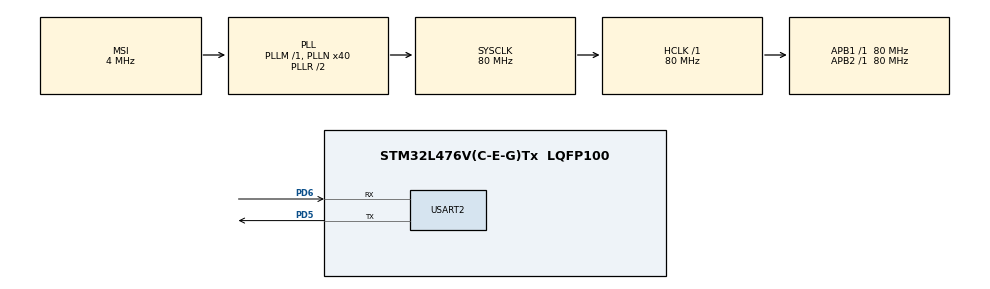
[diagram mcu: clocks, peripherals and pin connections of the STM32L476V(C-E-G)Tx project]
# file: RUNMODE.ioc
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Mcu.Family=STM32L4
Mcu.Name=STM32L476V(C-E-G)Tx
Mcu.Package=LQFP100
NVIC.PriorityGroup=NVIC_PRIORITYGROUP_4
PA13.Mode=Serial-Wire
PA13.Signal=SYS_JTMS-SWDIO
PA14.Mode=Serial-Wire
PA14.Signal=SYS_JTCK-SWCLK
PD5.Mode=Asynchronous
PD5.Signal=USART2_TX
PD6.Mode=Asynchronous
PD6.Signal=USART2_RX
ProjectManager.TargetToolchain=EWARM
RCC.ADCFreq_Value=16000000
RCC.AHBFreq_Value=80000000
RCC.APB1Freq_Value=80000000
RCC.APB1TimFreq_Value=80000000
RCC.APB2Freq_Value=80000000
RCC.APB2TimFreq_Value=80000000
RCC.CortexFreq_Value=80000000
RCC.HCLKFreq_Value=80000000
RCC.HSE_VALUE=8000000
RCC.HSI_VALUE=16000000
RCC.LSE_VALUE=32768
RCC.MSI_VALUE=4000000
RCC.PLLN=40
RCC.SYSCLKFreq_VALUE=80000000
RCC.SYSCLKSource=RCC_SYSCLKSOURCE_PLLCLK
RCC.USBFreq_Value=16000000
RCC.VCOOutputFreq_Value=160000000
TIM2.Period=0xFFFFFFFF
USART2.WordLength=UART_WORDLENGTH_8B
VP_TIM2_VS_ClockSourceINT.Mode=Internal
board=RUNMODE

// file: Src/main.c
/**
  ******************************************************************************
  * File Name          : main.c
  * Description        : Main program body
  ******************************************************************************
  *
  * COPYRIGHT(c) 2015 STMicroelectronics
  *
  * Redistribution and use in source and binary forms, with or without modification,
  * are permitted provided that the following conditions are met:
  *   1. Redistributions of source code must retain the above copyright notice,
  *      this list of conditions and the following disclaimer.
  *   2. Redistributions in binary form must reproduce the above copyright notice,
  *      this list of conditions and the following disclaimer in the documentation
  *      and/or other materials provided with the distribution.
  *   3. Neither the name of STMicroelectronics nor the names of its contributors
  *      may be used to endorse or promote products derived from this software
  *      without specific prior written permission.
  *
  * THIS SOFTWARE IS PROVIDED BY THE COPYRIGHT HOLDERS AND CONTRIBUTORS "AS IS"
  * AND ANY EXPRESS OR IMPLIED WARRANTIES, INCLUDING, BUT NOT LIMITED TO, THE
  * IMPLIED WARRANTIES OF MERCHANTABILITY AND FITNESS FOR A PARTICULAR PURPOSE ARE
  * DISCLAIMED. IN NO EVENT SHALL THE COPYRIGHT HOLDER OR CONTRIBUTORS BE LIABLE
  * FOR ANY DIRECT, INDIRECT, INCIDENTAL, SPECIAL, EXEMPLARY, OR CONSEQUENTIAL
  * DAMAGES (INCLUDING, BUT NOT LIMITED TO, PROCUREMENT OF SUBSTITUTE GOODS OR
  * SERVICES; LOSS OF USE, DATA, OR PROFITS; OR BUSINESS INTERRUPTION) HOWEVER
  * CAUSED AND ON ANY THEORY OF LIABILITY, WHETHER IN CONTRACT, STRICT LIABILITY,
  * OR TORT (INCLUDING NEGLIGENCE OR OTHERWISE) ARISING IN ANY WAY OUT OF THE USE
  * OF THIS SOFTWARE, EVEN IF ADVISED OF THE POSSIBILITY OF SUCH DAMAGE.
  *
  ******************************************************************************
  */
#include "stm32l4xx_hal.h"

/* USER CODE BEGIN Includes */
#include <stdio.h>
#include "coremark.h"
/* USER CODE END Includes */

TIM_HandleTypeDef htim2;

UART_HandleTypeDef huart2;

/* USER CODE BEGIN PV */
/* Private variables ---------------------------------------------------------*/
//struct __FILE { int dummy;};
//FILE __stdout;

/* USER CODE END PV */

void SystemClock_Config(void);
static void MX_GPIO_Init(void);
static void MX_TIM2_Init(void);
static void MX_USART2_UART_Init(void);

/* USER CODE BEGIN PFP */
/* Private function prototypes -----------------------------------------------*/
static void ART_Disable(void);
static void SystemClock_Config_MSI_24MHZ(void);
static void Clock_MSI24MHZ_Enable(void);

/* USER CODE END PFP */

int main(void)
{

  /* MCU Configuration----------------------------------------------------------*/

  /* Reset of all peripherals, Initializes the Flash interface and the Systick. */
  HAL_Init();

  /* Configure the system clock */
  SystemClock_Config();

  /* Initialize all configured peripherals */
  MX_GPIO_Init();
  MX_TIM2_Init();
  MX_USART2_UART_Init();

  /* USER CODE BEGIN 2 */

  //TPI->ACPR = (HAL_RCC_GetSysClockFreq() / 2000000) - 1; // make the SWO working whatever settings in the system frequency - output is always 2MHz

  //ART_Disable();
  //Clock_MSI24MHZ_Enable();

  HAL_TIM_Base_Start(&htim2);

  printf("\n");
  printf("Running from address:   0x%08X \n", (uint32_t)main_coremark);
  printf("Data at address: 0x%08X \n", (uint32_t)&default_num_contexts);
  //printf("WS: %2d, I_cache: %s, D_cache: %s, Prefetch: %s\n", FLASH->ACR & 0x0007, (FLASH->ACR & 0x0200)? "ON ":"OFF", ((FLASH->ACR & 0x0400)? "ON ":"OFF"), ((FLASH->ACR & 0x0100)? "ON ":"OFF"));
  printf("WS: %2d, ART: %s\n", FLASH->ACR & 0x0007, (FLASH->ACR & 0x0200)? "ON ":"OFF");
  printf("System Clock: %9d\n", HAL_RCC_GetSysClockFreq() );

  main_coremark();

  /* USER CODE END 2 */

  /* Infinite loop */
  while (1)
  {

  }

}

/** System Clock Configuration
*/
void SystemClock_Config(void)
{

  RCC_OscInitTypeDef RCC_OscInitStruct;
  RCC_ClkInitTypeDef RCC_ClkInitStruct;
  RCC_PeriphCLKInitTypeDef PeriphClkInit;

  RCC_OscInitStruct.OscillatorType = RCC_OSCILLATORTYPE_MSI;
  RCC_OscInitStruct.MSIState = RCC_MSI_ON;
  RCC_OscInitStruct.MSICalibrationValue = 0;
  RCC_OscInitStruct.MSIClockRange = RCC_MSIRANGE_6;
  RCC_OscInitStruct.PLL.PLLState = RCC_PLL_ON;
  RCC_OscInitStruct.PLL.PLLSource = RCC_PLLSOURCE_MSI;
  RCC_OscInitStruct.PLL.PLLM = 1;
  RCC_OscInitStruct.PLL.PLLN = 40;
  RCC_OscInitStruct.PLL.PLLP = RCC_PLLP_DIV7;
  RCC_OscInitStruct.PLL.PLLQ = RCC_PLLQ_DIV2;
  RCC_OscInitStruct.PLL.PLLR = RCC_PLLR_DIV2;
  HAL_RCC_OscConfig(&RCC_OscInitStruct);

  RCC_ClkInitStruct.ClockType = RCC_CLOCKTYPE_HCLK|RCC_CLOCKTYPE_SYSCLK
                              |RCC_CLOCKTYPE_PCLK1|RCC_CLOCKTYPE_PCLK2;
  RCC_ClkInitStruct.SYSCLKSource = RCC_SYSCLKSOURCE_PLLCLK;
  RCC_ClkInitStruct.AHBCLKDivider = RCC_SYSCLK_DIV1;
  RCC_ClkInitStruct.APB1CLKDivider = RCC_HCLK_DIV1;
  RCC_ClkInitStruct.APB2CLKDivider = RCC_HCLK_DIV1;
  HAL_RCC_ClockConfig(&RCC_ClkInitStruct, FLASH_LATENCY_4);

  PeriphClkInit.PeriphClockSelection = RCC_PERIPHCLK_USART2;
  PeriphClkInit.Usart2ClockSelection = RCC_USART2CLKSOURCE_PCLK1;
  HAL_RCCEx_PeriphCLKConfig(&PeriphClkInit);

  __PWR_CLK_ENABLE();

  HAL_PWREx_ControlVoltageScaling(PWR_REGULATOR_VOLTAGE_SCALE1);

  HAL_SYSTICK_Config(HAL_RCC_GetHCLKFreq()/1000);

  HAL_SYSTICK_CLKSourceConfig(SYSTICK_CLKSOURCE_HCLK);

  /* SysTick_IRQn interrupt configuration */
  HAL_NVIC_SetPriority(SysTick_IRQn, 0, 0);
}

/* TIM2 init function */
void MX_TIM2_Init(void)
{

  TIM_ClockConfigTypeDef sClockSourceConfig;
  TIM_MasterConfigTypeDef sMasterConfig;

  htim2.Instance = TIM2;
  htim2.Init.Prescaler = 0;
  htim2.Init.CounterMode = TIM_COUNTERMODE_UP;
  htim2.Init.Period = 0xFFFFFFFF;
  htim2.Init.ClockDivision = TIM_CLOCKDIVISION_DIV1;
  HAL_TIM_Base_Init(&htim2);

  sClockSourceConfig.ClockSource = TIM_CLOCKSOURCE_INTERNAL;
  HAL_TIM_ConfigClockSource(&htim2, &sClockSourceConfig);

  sMasterConfig.MasterOutputTrigger = TIM_TRGO_RESET;
  sMasterConfig.MasterSlaveMode = TIM_MASTERSLAVEMODE_DISABLE;
  HAL_TIMEx_MasterConfigSynchronization(&htim2, &sMasterConfig);

}

/* USART2 init function */
void MX_USART2_UART_Init(void)
{

  huart2.Instance = USART2;
  huart2.Init.BaudRate = 115200;
  huart2.Init.WordLength = UART_WORDLENGTH_8B;
  huart2.Init.StopBits = UART_STOPBITS_1;
  huart2.Init.Parity = UART_PARITY_NONE;
  huart2.Init.Mode = UART_MODE_TX_RX;
  huart2.Init.HwFlowCtl = UART_HWCONTROL_NONE;
  huart2.Init.OverSampling = UART_OVERSAMPLING_16;
  huart2.Init.OneBitSampling = UART_ONEBIT_SAMPLING_DISABLED;
  huart2.AdvancedInit.AdvFeatureInit = UART_ADVFEATURE_NO_INIT;
  HAL_UART_Init(&huart2);

}

/** Configure pins as
        * Analog
        * Input
        * Output
        * EVENT_OUT
        * EXTI
        * Free pins are configured automatically as Analog (this feature is enabled through
        * the Code Generation settings)
*/
void MX_GPIO_Init(void)
{

  GPIO_InitTypeDef GPIO_InitStruct;

  /* GPIO Ports Clock Enable */
  __GPIOE_CLK_ENABLE();
  __GPIOC_CLK_ENABLE();
  __GPIOH_CLK_ENABLE();
  __GPIOA_CLK_ENABLE();
  __GPIOB_CLK_ENABLE();
  __GPIOD_CLK_ENABLE();

  /*Configure GPIO pins : PE2 PE3 PE4 PE5
                           PE6 PE7 PE8 PE9
                           PE10 PE11 PE12 PE13
                           PE14 PE15 PE0 PE1 */
  GPIO_InitStruct.Pin = GPIO_PIN_2|GPIO_PIN_3|GPIO_PIN_4|GPIO_PIN_5
                          |GPIO_PIN_6|GPIO_PIN_7|GPIO_PIN_8|GPIO_PIN_9
                          |GPIO_PIN_10|GPIO_PIN_11|GPIO_PIN_12|GPIO_PIN_13
                          |GPIO_PIN_14|GPIO_PIN_15|GPIO_PIN_0|GPIO_PIN_1;
  GPIO_InitStruct.Mode = GPIO_MODE_ANALOG;
  GPIO_InitStruct.Pull = GPIO_NOPULL;
  HAL_GPIO_Init(GPIOE, &GPIO_InitStruct);

  /*Configure GPIO pins : PC13 PC14 PC15 PC0
                           PC1 PC2 PC3 PC4
                           PC5 PC6 PC7 PC8
                           PC9 PC10 PC11 PC12 */
  GPIO_InitStruct.Pin = GPIO_PIN_13|GPIO_PIN_14|GPIO_PIN_15|GPIO_PIN_0
                          |GPIO_PIN_1|GPIO_PIN_2|GPIO_PIN_3|GPIO_PIN_4
                          |GPIO_PIN_5|GPIO_PIN_6|GPIO_PIN_7|GPIO_PIN_8
                          |GPIO_PIN_9|GPIO_PIN_10|GPIO_PIN_11|GPIO_PIN_12;
  GPIO_InitStruct.Mode = GPIO_MODE_ANALOG;
  GPIO_InitStruct.Pull = GPIO_NOPULL;
  HAL_GPIO_Init(GPIOC, &GPIO_InitStruct);

  /*Configure GPIO pins : PH0 PH1 */
  GPIO_InitStruct.Pin = GPIO_PIN_0|GPIO_PIN_1;
  GPIO_InitStruct.Mode = GPIO_MODE_ANALOG;
  GPIO_InitStruct.Pull = GPIO_NOPULL;
  HAL_GPIO_Init(GPIOH, &GPIO_InitStruct);

  /*Configure GPIO pins : PA0 PA1 PA2 PA3
                           PA4 PA5 PA6 PA7
                           PA8 PA9 PA10 PA11
                           PA12 PA15 */
  GPIO_InitStruct.Pin = GPIO_PIN_0|GPIO_PIN_1|GPIO_PIN_2|GPIO_PIN_3
                          |GPIO_PIN_4|GPIO_PIN_5|GPIO_PIN_6|GPIO_PIN_7
                          |GPIO_PIN_8|GPIO_PIN_9|GPIO_PIN_10|GPIO_PIN_11
                          |GPIO_PIN_12|GPIO_PIN_15;
  GPIO_InitStruct.Mode = GPIO_MODE_ANALOG;
  GPIO_InitStruct.Pull = GPIO_NOPULL;
  HAL_GPIO_Init(GPIOA, &GPIO_InitStruct);

  /*Configure GPIO pins : PB0 PB1 PB2 PB10
                           PB11 PB12 PB13 PB14
                           PB15 PB3 PB4 PB5
                           PB6 PB7 PB8 PB9 */
  GPIO_InitStruct.Pin = GPIO_PIN_0|GPIO_PIN_1|GPIO_PIN_2|GPIO_PIN_10
                          |GPIO_PIN_11|GPIO_PIN_12|GPIO_PIN_13|GPIO_PIN_14
                          |GPIO_PIN_15|GPIO_PIN_3|GPIO_PIN_4|GPIO_PIN_5
                          |GPIO_PIN_6|GPIO_PIN_7|GPIO_PIN_8|GPIO_PIN_9;
  GPIO_InitStruct.Mode = GPIO_MODE_ANALOG;
  GPIO_InitStruct.Pull = GPIO_NOPULL;
  HAL_GPIO_Init(GPIOB, &GPIO_InitStruct);

  /*Configure GPIO pins : PD8 PD9 PD10 PD11
                           PD12 PD13 PD14 PD15
                           PD0 PD1 PD2 PD3
                           PD4 PD7 */
  GPIO_InitStruct.Pin = GPIO_PIN_8|GPIO_PIN_9|GPIO_PIN_10|GPIO_PIN_11
                          |GPIO_PIN_12|GPIO_PIN_13|GPIO_PIN_14|GPIO_PIN_15
                          |GPIO_PIN_0|GPIO_PIN_1|GPIO_PIN_2|GPIO_PIN_3
                          |GPIO_PIN_4|GPIO_PIN_7;
  GPIO_InitStruct.Mode = GPIO_MODE_ANALOG;
  GPIO_InitStruct.Pull = GPIO_NOPULL;
  HAL_GPIO_Init(GPIOD, &GPIO_InitStruct);

}

/* USER CODE BEGIN 4 */

int fputc(int ch, FILE *f)
{
uint8_t c[1];

  c[0] = ch & 0x00FF;

  HAL_UART_Transmit(&huart2,&*c,1,10);

  return(ch);
}

void ART_Disable(void)
{
  __HAL_FLASH_INSTRUCTION_CACHE_DISABLE();
  __HAL_FLASH_DATA_CACHE_DISABLE();
}

void SystemClock_Config_MSI_24MHZ(void)
{

  RCC_OscInitTypeDef RCC_OscInitStruct;
  RCC_ClkInitTypeDef RCC_ClkInitStruct;

  RCC_OscInitStruct.OscillatorType = RCC_OSCILLATORTYPE_MSI;
  RCC_OscInitStruct.MSIState = RCC_MSI_ON;
  RCC_OscInitStruct.MSICalibrationValue = 0;
  RCC_OscInitStruct.MSIClockRange = RCC_MSIRANGE_9;
  RCC_OscInitStruct.PLL.PLLState = RCC_PLL_NONE;
  HAL_RCC_OscConfig(&RCC_OscInitStruct);

  RCC_ClkInitStruct.ClockType = RCC_CLOCKTYPE_HCLK|RCC_CLOCKTYPE_SYSCLK
                              |RCC_CLOCKTYPE_PCLK1|RCC_CLOCKTYPE_PCLK2;
  RCC_ClkInitStruct.SYSCLKSource = RCC_SYSCLKSOURCE_MSI;
  RCC_ClkInitStruct.AHBCLKDivider = RCC_SYSCLK_DIV1;
  RCC_ClkInitStruct.APB1CLKDivider = RCC_HCLK_DIV1;
  RCC_ClkInitStruct.APB2CLKDivider = RCC_HCLK_DIV1;
  HAL_RCC_ClockConfig(&RCC_ClkInitStruct, FLASH_LATENCY_1);

  __PWR_CLK_ENABLE();

  HAL_PWREx_ControlVoltageScaling(PWR_REGULATOR_VOLTAGE_SCALE1);

  HAL_SYSTICK_Config(HAL_RCC_GetHCLKFreq()/1000);

  HAL_SYSTICK_CLKSourceConfig(SYSTICK_CLKSOURCE_HCLK);

  /* SysTick_IRQn interrupt configuration */
  HAL_NVIC_SetPriority(SysTick_IRQn, 0, 0);
}

void Clock_MSI24MHZ_Enable(void)
{
  SystemClock_Config_MSI_24MHZ();
  MX_USART2_UART_Init();
}

/* USER CODE END 4 */

/************************ (C) COPYRIGHT STMicroelectronics *****END OF FILE****/
